# ATmega324PB register map
Vendor: Atmel; File version: 1.0
CPU: other r0p0, little endian, no MPU, no FPU, 4 interrupt priority bits
Registers are 8-bit, read-write, reset 0x0 unless marked. A register's access mark holds for its fields unless they carry their own. Offsets are from the block's base; [hi:lo] are bit positions.

## TWI0 — Two Wire Serial Interface
Base 0x008000B8
0x00 TWBR0 — TWI Bit Rate register
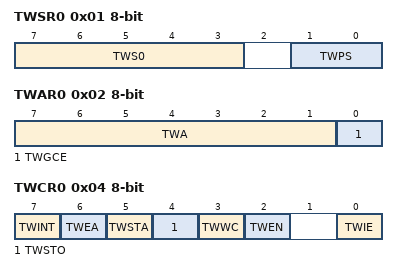
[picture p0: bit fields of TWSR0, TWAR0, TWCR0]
0x01 TWSR0 — TWI Status Register
  [7:3] TWS0 — TWI Status
  [1:0] TWPS — TWI Prescaler
    0=1; 1=4; 2=16; 3=64
0x02 TWAR0 — TWI (Slave) Address register
  [7:1] TWA — TWI (Slave) Address register Bits
  [0] TWGCE — TWI General Call Recognition Enable Bit
0x03 TWDR0 — TWI Data register
0x04 TWCR0 — TWI Control Register (read-only for debugger)
  [7] TWINT — TWI Interrupt Flag
  [6] TWEA — TWI Enable Acknowledge Bit
  [5] TWSTA — TWI Start Condition Bit
  [4] TWSTO — TWI Stop Condition Bit
  [3] TWWC — TWI Write Collision Flag
  [2] TWEN — TWI Enable Bit
  [0] TWIE — TWI Interrupt Enable
0x05 TWAMR0 — TWI (Slave) Address Mask Register
  [7:1] TWAM0

## TWI1 — Two Wire Serial Interface
Base 0x008000D8
0x00 TWBR1 — TWI Bit Rate register
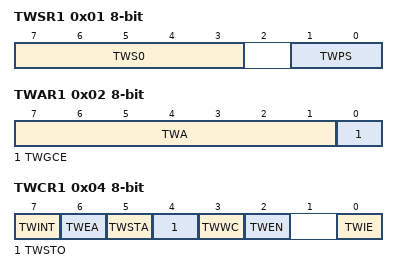
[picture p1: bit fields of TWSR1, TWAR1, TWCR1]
0x01 TWSR1 — TWI Status Register
  [7:3] TWS0 — TWI Status
  [1:0] TWPS — TWI Prescaler
    0=1; 1=4; 2=16; 3=64
0x02 TWAR1 — TWI (Slave) Address register
  [7:1] TWA — TWI (Slave) Address register Bits
  [0] TWGCE — TWI General Call Recognition Enable Bit
0x03 TWDR1 — TWI Data register
0x04 TWCR1 — TWI Control Register (read-only for debugger)
  [7] TWINT — TWI Interrupt Flag
  [6] TWEA — TWI Enable Acknowledge Bit
  [5] TWSTA — TWI Start Condition Bit
  [4] TWSTO — TWI Stop Condition Bit
  [3] TWWC — TWI Write Collision Flag
  [2] TWEN — TWI Enable Bit
  [0] TWIE — TWI Interrupt Enable
0x05 TWAMR1 — TWI (Slave) Address Mask Register
  [7:1] TWAM1

## USART0 — USART
Base 0x008000C0
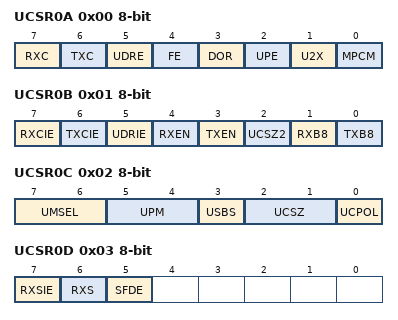
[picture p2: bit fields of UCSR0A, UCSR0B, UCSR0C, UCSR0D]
0x00 UCSR0A — USART Control and Status Register A (read-only for debugger)
  [7] RXC ro — USART Receive Complete
  [6] TXC — USART Transmit Complete
  [5] UDRE ro — USART Data Register Empty
  [4] FE ro — Framing Error
  [3] DOR ro — Data Overrun
  [2] UPE ro — Parity Error
  [1] U2X — Double the USART transmission speed
  [0] MPCM — Multi-processor Communication Mode
0x01 UCSR0B — USART Control and Status Register B
  [7] RXCIE — RX Complete Interrupt Enable
  [6] TXCIE — TX Complete Interrupt Enable
  [5] UDRIE — USART Data register Empty Interrupt Enable
  [4] RXEN — Receiver Enable
  [3] TXEN — Transmitter Enable
  [2] UCSZ2 — Character Size
  [1] RXB8 — Receive Data Bit 8
  [0] TXB8 — Transmit Data Bit 8
0x02 UCSR0C — USART Control and Status Register C
  [7:6] UMSEL — USART Mode Select
    0=ASYNCHRONOUS_OPERATION; 1=SYNCHRONOUS_OPERATION; 3=MASTER_SPI
  [5:4] UPM — Parity Mode Bits
    0=DISABLED; 2=ENABLED_EVEN_PARITY; 3=ENABLED_ODD_PARITY
  [3] USBS — Stop Bit Select
    0=1_BIT; 1=2_BIT
  [2:1] UCSZ — Character Size
  [0] UCPOL — Clock Polarity
0x03 UCSR0D — USART Control and Status Register D
  [7] RXSIE — RX Start Frame Interrupt Enable
  [6] RXS — Start Frame Detect Flag
  [5] SFDE — Start Frame Detection Enable
0x04 UBRR0 16-bit (reset mask 0xFF) — USART Baud Rate Register Bytes
0x06 UDR0 — USART I/O Data Register (write-only for debugger)

## USART1 — USART
Base 0x008000C8
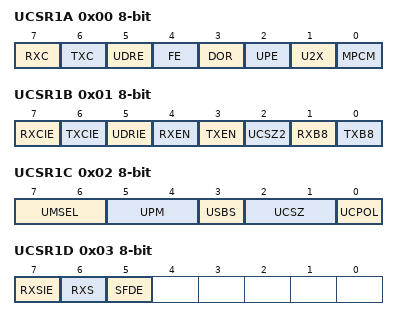
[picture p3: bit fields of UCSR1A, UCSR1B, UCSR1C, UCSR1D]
0x00 UCSR1A — USART Control and Status Register A (read-only for debugger)
  [7] RXC ro — USART Receive Complete
  [6] TXC — USART Transmit Complete
  [5] UDRE ro — USART Data Register Empty
  [4] FE ro — Framing Error
  [3] DOR ro — Data Overrun
  [2] UPE ro — Parity Error
  [1] U2X — Double the USART transmission speed
  [0] MPCM — Multi-processor Communication Mode
0x01 UCSR1B — USART Control and Status Register B
  [7] RXCIE — RX Complete Interrupt Enable
  [6] TXCIE — TX Complete Interrupt Enable
  [5] UDRIE — USART Data register Empty Interrupt Enable
  [4] RXEN — Receiver Enable
  [3] TXEN — Transmitter Enable
  [2] UCSZ2 — Character Size
  [1] RXB8 — Receive Data Bit 8
  [0] TXB8 — Transmit Data Bit 8
0x02 UCSR1C — USART Control and Status Register C
  [7:6] UMSEL — USART Mode Select
    0=ASYNCHRONOUS_OPERATION; 1=SYNCHRONOUS_OPERATION; 3=MASTER_SPI
  [5:4] UPM — Parity Mode Bits
    0=DISABLED; 2=ENABLED_EVEN_PARITY; 3=ENABLED_ODD_PARITY
  [3] USBS — Stop Bit Select
    0=1_BIT; 1=2_BIT
  [2:1] UCSZ — Character Size
  [0] UCPOL — Clock Polarity
0x03 UCSR1D — USART Control and Status Register D
  [7] RXSIE — RX Start Frame Interrupt Enable
  [6] RXS — Start Frame Detect Flag
  [5] SFDE — Start Frame Detection Enable
0x04 UBRR1 16-bit (reset mask 0xFF) — USART Baud Rate Register Bytes
0x06 UDR1 — USART I/O Data Register (write-only for debugger)

## USART2 — USART
Base 0x008000D0
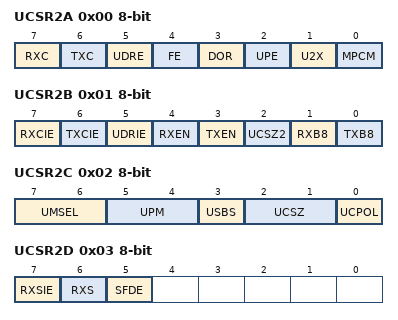
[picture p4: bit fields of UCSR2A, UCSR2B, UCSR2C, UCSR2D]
0x00 UCSR2A — USART Control and Status Register A (read-only for debugger)
  [7] RXC ro — USART Receive Complete
  [6] TXC — USART Transmit Complete
  [5] UDRE ro — USART Data Register Empty
  [4] FE ro — Framing Error
  [3] DOR ro — Data Overrun
  [2] UPE ro — Parity Error
  [1] U2X — Double the USART transmission speed
  [0] MPCM — Multi-processor Communication Mode
0x01 UCSR2B — USART Control and Status Register B
  [7] RXCIE — RX Complete Interrupt Enable
  [6] TXCIE — TX Complete Interrupt Enable
  [5] UDRIE — USART Data register Empty Interrupt Enable
  [4] RXEN — Receiver Enable
  [3] TXEN — Transmitter Enable
  [2] UCSZ2 — Character Size
  [1] RXB8 — Receive Data Bit 8
  [0] TXB8 — Transmit Data Bit 8
0x02 UCSR2C — USART Control and Status Register C
  [7:6] UMSEL — USART Mode Select
    0=ASYNCHRONOUS_OPERATION; 1=SYNCHRONOUS_OPERATION; 3=MASTER_SPI
  [5:4] UPM — Parity Mode Bits
    0=DISABLED; 2=ENABLED_EVEN_PARITY; 3=ENABLED_ODD_PARITY
  [3] USBS — Stop Bit Select
    0=1_BIT; 1=2_BIT
  [2:1] UCSZ — Character Size
  [0] UCPOL — Clock Polarity
0x03 UCSR2D — USART Control and Status Register D
  [7] RXSIE — RX Start Frame Interrupt Enable
  [6] RXS — Start Frame Detect Flag
  [5] SFDE — Start Frame Detection Enable
0x04 UBRR2 16-bit (reset mask 0xFF) — USART Baud Rate Register Bytes
0x06 UDR2 — USART I/O Data Register (write-only for debugger)

## WDT — Watchdog Timer
Base 0x00800060
0x00 WDTCSR — Watchdog Timer Control Register (read-only for debugger)
  [7] WDIF — Watchdog Timeout Interrupt Flag
  [6] WDIE — Watchdog Timeout Interrupt Enable
  [4] WDCE — Watchdog Change Enable
  [3] WDE — Watch Dog Enable
  [5:0] WDP — Watchdog Timer Prescaler Bits
    0=OSCILLATOR_CYCLES_2K; 1=OSCILLATOR_CYCLES_4K; 2=OSCILLATOR_CYCLES_8K; 3=OSCILLATOR_CYCLES_16K; 4=OSCILLATOR_CYCLES_32K; 5=OSCILLATOR_CYCLES_64K; 6=OSCILLATOR_CYCLES_128K; 7=OSCILLATOR_CYCLES_256K
